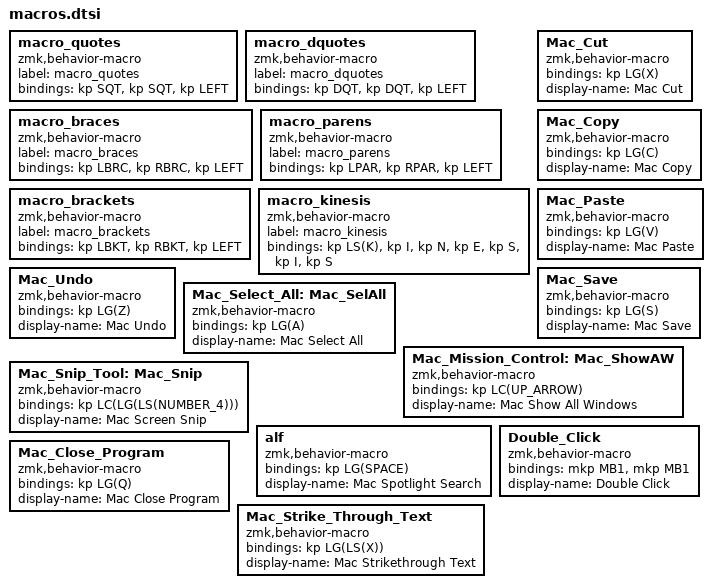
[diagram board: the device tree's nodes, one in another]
  macro_quotes: macro_quotes {
    compatible = "zmk,behavior-macro";
    label = "macro_quotes";
    #binding-cells = <0>;
    bindings = <&kp SQT>, <&kp SQT>, <&kp LEFT>;
  };
  macro_dquotes: macro_dquotes {
    compatible = "zmk,behavior-macro";
    label = "macro_dquotes";
    #binding-cells = <0>;
    bindings = <&kp DQT>, <&kp DQT>, <&kp LEFT>;
  };
  macro_braces: macro_braces {
    compatible = "zmk,behavior-macro";
    label = "macro_braces";
    #binding-cells = <0>;
    bindings = <&kp LBRC>, <&kp RBRC>, <&kp LEFT>;
  };
  macro_parens: macro_parens {
    compatible = "zmk,behavior-macro";
    label = "macro_parens";
    #binding-cells = <0>;
    bindings = <&kp LPAR>, <&kp RPAR>, <&kp LEFT>;
  };
  macro_brackets: macro_brackets {
    compatible = "zmk,behavior-macro";
    label = "macro_brackets";
    #binding-cells = <0>;
    bindings = <&kp LBKT>, <&kp RBKT>, <&kp LEFT>;
  };
  macro_kinesis: macro_kinesis {
    compatible = "zmk,behavior-macro";
    label = "macro_kinesis";
    #binding-cells = <0>;
    bindings = <&kp LS(K)>, <&kp I>, <&kp N>, <&kp E>, <&kp S>, <&kp I>, <&kp S>;
  };

  Mac_Cut: Mac_Cut {
    compatible = "zmk,behavior-macro";
    #binding-cells = <0>;
    bindings = <&kp LG(X)>;
    display-name = "Mac Cut";
  };

  Mac_Copy: Mac_Copy {
    compatible = "zmk,behavior-macro";
    #binding-cells = <0>;
    bindings = <&kp LG(C)>;
    display-name = "Mac Copy";
  };

  Mac_Paste: Mac_Paste {
    compatible = "zmk,behavior-macro";
    #binding-cells = <0>;
    bindings = <&kp LG(V)>;
    display-name = "Mac Paste";
  };

  Mac_Undo: Mac_Undo {
    compatible = "zmk,behavior-macro";
    #binding-cells = <0>;
    bindings = <&kp LG(Z)>;
    display-name = "Mac Undo";
  };

  Mac_Select_All: Mac_SelAll {
    compatible = "zmk,behavior-macro";
    #binding-cells = <0>;
    bindings = <&kp LG(A)>;
    display-name = "Mac Select All";
  };

  Mac_Save: Mac_Save {
    compatible = "zmk,behavior-macro";
    #binding-cells = <0>;
    bindings = <&kp LG(S)>;
    display-name = "Mac Save";
  };

  Mac_Mission_Control: Mac_ShowAW {
    compatible = "zmk,behavior-macro";
    #binding-cells = <0>;
    bindings = <&kp LC(UP_ARROW)>;
    display-name = "Mac Show All Windows";
  };

  Mac_Snip_Tool: Mac_Snip {
    compatible = "zmk,behavior-macro";
    #binding-cells = <0>;
    bindings = <&kp LC(LG(LS(NUMBER_4)))>;
    display-name = "Mac Screen Snip";
  };

  alf: alf {
    compatible = "zmk,behavior-macro";
    #binding-cells = <0>;
    bindings = <&kp LG(SPACE)>;
    display-name = "Mac Spotlight Search";
  };

  Mac_Close_Program: Mac_Close_Program {
    compatible = "zmk,behavior-macro";
    #binding-cells = <0>;
    bindings = <&kp LG(Q)>;
    display-name = "Mac Close Program";
  };

  Mac_Strike_Through_Text: Mac_Strike_Through_Text {
    compatible = "zmk,behavior-macro";
    #binding-cells = <0>;
    bindings = <&kp LG(LS(X))>;
    display-name = "Mac Strikethrough Text";
  };

  Double_Click: Double_Click {
    compatible = "zmk,behavior-macro";
    #binding-cells = <0>;
    bindings = <&mkp MB1 &mkp MB1>;
    display-name = "Double Click";
  };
